VERSION "created by canmatrix"

NS_ :

BS_:

BU_:

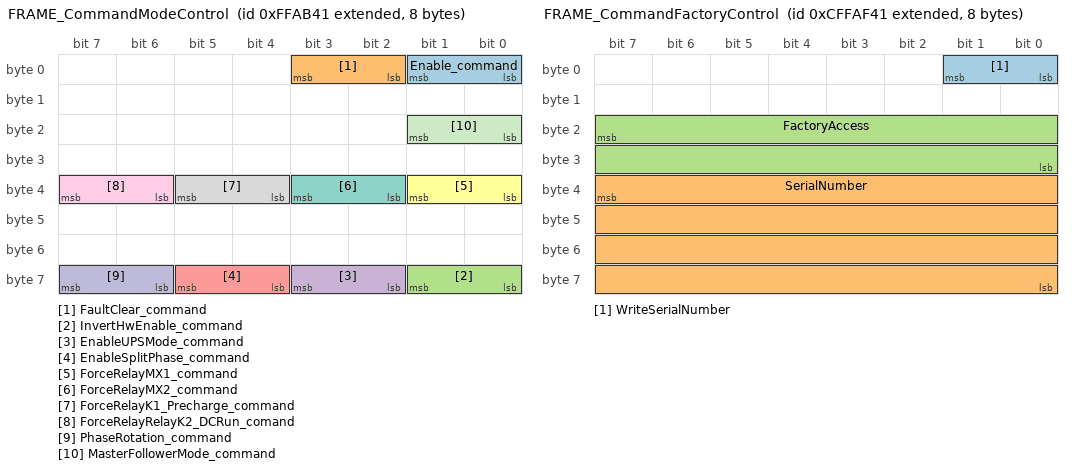
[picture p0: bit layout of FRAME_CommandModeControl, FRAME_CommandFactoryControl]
BO_ 2164239169 FRAME_CommandModeControl: 8 Vector__XXX
 SG_ Enable_command : 1|2@0+ (1,0) [0.0|3.0] "" Vector__XXX
 SG_ FaultClear_command : 3|2@0+ (1,0) [0.0|3.0] "" Vector__XXX
 SG_ InvertHwEnable_command : 57|2@0+ (1,0) [0.0|3.0] "" Vector__XXX
 SG_ EnableUPSMode_command : 59|2@0+ (1,0) [0.0|3.0] "" Vector__XXX
 SG_ EnableSplitPhase_command : 61|2@0+ (1,0) [0.0|3.0] "" Vector__XXX
 SG_ ForceRelayMX1_command : 33|2@0+ (1,0) [0.0|3.0] "" Vector__XXX
 SG_ ForceRelayMX2_command : 35|2@0+ (1,0) [0.0|3.0] "" Vector__XXX
 SG_ ForceRelayK1_Precharge_command : 37|2@0+ (1,0) [0.0|3.0] "" Vector__XXX
 SG_ ForceRelayRelayK2_DCRun_comand : 39|2@0+ (1,0) [0.0|3.0] "" Vector__XXX
 SG_ PhaseRotation_command : 63|2@0+ (1,0) [0.0|3.0] "" Vector__XXX
 SG_ MasterFollowerMode_command : 17|2@0+ (1,0) [0.0|3.0] "" Vector__XXX

BO_ 2365566017 FRAME_CommandPower: 8 Vector__XXX
 SG_ RealPower_command : 7|32@0+ (1,0) [0.0|4294967295.0] "" Vector__XXX
 SG_ ReactivePower_command : 39|32@0+ (1,0) [0.0|4294967295.0] "" Vector__XXX

BO_ 2365566529 FRAME_CommandVF: 8 Vector__XXX
 SG_ Voltage_command : 7|16@0+ (0.1,0) [0.0|6553.5] "" Vector__XXX
 SG_ Frequency_command : 23|16@0+ (0.1,0) [0.0|6553.5] "" Vector__XXX

BO_ 2365573878 FRAME_MasterMeasuredPower: 8 Vector__XXX
 SG_ RealPower_measured : 7|32@0+ (1,0) [0.0|4294967295.0] "" Vector__XXX
 SG_ ReactivePower_measured : 39|32@0+ (1,0) [0.0|4294967295.0] "" Vector__XXX

BO_ 2365566785 FRAME_CommandFactoryControl: 8 Vector__XXX
 SG_ WriteSerialNumber : 1|2@0+ (1,0) [0.0|3.0] "" Vector__XXX
 SG_ SerialNumber : 39|32@0+ (1,0) [0.0|4294967295.0] "" Vector__XXX
 SG_ FactoryAccess : 23|16@0+ (1,0) [0.0|65535.0] "" Vector__XXX

BO_ 2365565505 FRAME_CommandSetNVParam: 8 Vector__XXX
 SG_ CommandSetNVParam_MUX : 7|16@0+ (1,0) [0.0|65535.0] "" Vector__XXX
 SG_ Dummy : 23|16@0+ (1,0) [0.0|65535.0] "" Vector__XXX
 SG_ VUnder50pct : 23|16@0+ (1,0) [0.0|65535.0] "" Vector__XXX
 SG_ V50to88pct : 39|16@0+ (1,0) [0.0|65535.0] "" Vector__XXX
 SG_ V110to120pct : 55|16@0+ (1,0) [0.0|65535.0] "" Vector__XXX
 SG_ VOver120 : 23|16@0+ (1,0) [0.0|65535.0] "" Vector__XXX
 SG_ FreqHi : 23|16@0+ (0.1,0) [0.0|6553.5] "" Vector__XXX
 SG_ FreqLo : 39|16@0+ (0.1,0) [0.0|6553.5] "" Vector__XXX
 SG_ FreqVeryLo : 55|16@0+ (0.1,0) [0.0|6553.5] "" Vector__XXX
 SG_ FreqVeryLo : 23|16@0+ (0.1,0) [0.0|6553.5] "" Vector__XXX
 SG_ FreqLo : 39|16@0+ (0.1,0) [0.0|6553.5] "" Vector__XXX
 SG_ FreqHi : 55|16@0+ (0.1,0) [0.0|6553.5] "" Vector__XXX
 SG_ NodeID : 23|8@0+ (1,0) [0.0|255.0] "" Vector__XXX
 SG_ SA_Mask : 31|8@0+ (1,0) [0.0|255.0] "" Vector__XXX
 SG_ Baudrate : 39|4@0+ (1,0) [0.0|15.0] "" Vector__XXX
 SG_ ThermalOverload : 17|2@0+ (1,0) [0.0|3.0] "" Vector__XXX
 SG_ MX1Open : 23|16@0+ (1,0) [0.0|65535.0] "" Vector__XXX
 SG_ MX1Close : 39|16@0+ (1,0) [0.0|65535.0] "" Vector__XXX
 SG_ MX2Open : 55|16@0+ (1,0) [0.0|65535.0] "" Vector__XXX
 SG_ MX2Close : 23|16@0+ (1,0) [0.0|65535.0] "" Vector__XXX
 SG_ K1Open : 39|16@0+ (1,0) [0.0|65535.0] "" Vector__XXX
 SG_ K1Close : 55|16@0+ (1,0) [0.0|65535.0] "" Vector__XXX
 SG_ K2Open : 23|16@0+ (1,0) [0.0|65535.0] "" Vector__XXX
 SG_ K2Close : 39|16@0+ (1,0) [0.0|65535.0] "" Vector__XXX

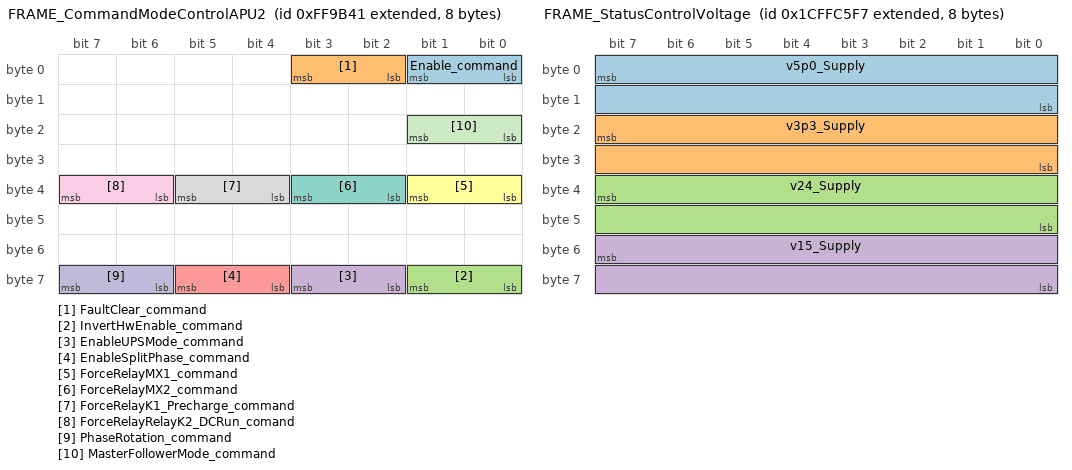
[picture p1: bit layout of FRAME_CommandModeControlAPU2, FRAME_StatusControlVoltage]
BO_ 2164235073 FRAME_CommandModeControlAPU2: 8 Vector__XXX
 SG_ Enable_command : 1|2@0+ (1,0) [0.0|3.0] "" Vector__XXX
 SG_ FaultClear_command : 3|2@0+ (1,0) [0.0|3.0] "" Vector__XXX
 SG_ InvertHwEnable_command : 57|2@0+ (1,0) [0.0|3.0] "" Vector__XXX
 SG_ EnableUPSMode_command : 59|2@0+ (1,0) [0.0|3.0] "" Vector__XXX
 SG_ EnableSplitPhase_command : 61|2@0+ (1,0) [0.0|3.0] "" Vector__XXX
 SG_ ForceRelayMX1_command : 33|2@0+ (1,0) [0.0|3.0] "" Vector__XXX
 SG_ ForceRelayMX2_command : 35|2@0+ (1,0) [0.0|3.0] "" Vector__XXX
 SG_ ForceRelayK1_Precharge_command : 37|2@0+ (1,0) [0.0|3.0] "" Vector__XXX
 SG_ ForceRelayRelayK2_DCRun_comand : 39|2@0+ (1,0) [0.0|3.0] "" Vector__XXX
 SG_ PhaseRotation_command : 63|2@0+ (1,0) [0.0|3.0] "" Vector__XXX
 SG_ MasterFollowerMode_command : 17|2@0+ (1,0) [0.0|3.0] "" Vector__XXX

BO_ 2365561921 FRAME_CommandPowerAPU2: 8 Vector__XXX
 SG_ RealPower_command : 7|32@0+ (1,0) [0.0|4294967295.0] "" Vector__XXX
 SG_ ReactivePower_command : 39|32@0+ (1,0) [0.0|4294967295.0] "" Vector__XXX

BO_ 2365562433 FRAME_CommandVFAPU2: 8 Vector__XXX
 SG_ Voltage_command : 7|16@0+ (0.1,0) [0.0|6553.5] "" Vector__XXX
 SG_ Frequency_command : 23|16@0+ (0.1,0) [0.0|6553.5] "" Vector__XXX

BO_ 2365573879 FRAME_MasterMeasuredPowerAPU2: 8 Vector__XXX
 SG_ RealPower_measured : 7|32@0+ (1,0) [0.0|4294967295.0] "" Vector__XXX
 SG_ ReactivePower_measured : 39|32@0+ (1,0) [0.0|4294967295.0] "" Vector__XXX

BO_ 2365573879 FRAME_StatusMeasuredPower: 8 Vector__XXX
 SG_ RealPower_measured : 7|32@0+ (1,0) [0.0|4294967295.0] "" Vector__XXX
 SG_ ReactivePower_measured : 39|32@0+ (1,0) [0.0|4294967295.0] "" Vector__XXX

BO_ 2566898935 FRAME_StatusCommandedPower: 8 Vector__XXX
 SG_ RealPower_echo : 7|32@0+ (1,0) [0.0|4294967295.0] "" Vector__XXX
 SG_ ReactivePower_echo : 39|32@0+ (1,0) [0.0|4294967295.0] "" Vector__XXX

BO_ 2365572087 FRAME_StatusBits: 8 Vector__XXX
 SG_ State_status : 3|4@0+ (1,0) [0.0|15.0] "" Vector__XXX
 SG_ MX2Permissive_status : 19|2@0+ (1,0) [0.0|3.0] "" Vector__XXX
 SG_ PowerAvailAC_status : 11|2@0+ (1,0) [0.0|3.0] "" Vector__XXX
 SG_ PowerAvailDC_status : 13|2@0+ (1,0) [0.0|3.0] "" Vector__XXX
 SG_ PowerCircuitEnabled_status : 15|2@0+ (1,0) [0.0|3.0] "" Vector__XXX
 SG_ HardwareEnable_status : 9|2@0+ (1,0) [0.0|3.0] "" Vector__XXX
 SG_ Enable_echo : 5|2@0+ (1,0) [0.0|3.0] "" Vector__XXX
 SG_ FaultClr_echo : 7|2@0+ (1,0) [0.0|3.0] "" Vector__XXX
 SG_ MessageValidModeControl_status : 25|2@0+ (1,0) [0.0|3.0] "" Vector__XXX
 SG_ MX1Permissive_status : 17|2@0+ (1,0) [0.0|3.0] "" Vector__XXX
 SG_ K2DCRunPermissive_status : 23|2@0+ (1,0) [0.0|3.0] "" Vector__XXX
 SG_ K1PrechargePermissive_status : 21|2@0+ (1,0) [0.0|3.0] "" Vector__XXX
 SG_ MessageValidPowerCMD_status : 27|2@0+ (1,0) [0.0|3.0] "" Vector__XXX
 SG_ MessageValidVF_status : 29|2@0+ (1,0) [0.0|3.0] "" Vector__XXX
 SG_ CANbus_status : 31|2@0+ (1,0) [0.0|3.0] "" Vector__XXX
 SG_ EnableUPSMode_echo : 33|2@0+ (1,0) [0.0|3.0] "" Vector__XXX
 SG_ EnableSplitPhase_echo : 35|2@0+ (1,0) [0.0|3.0] "" Vector__XXX
 SG_ PhaseRotation_status : 37|2@0+ (1,0) [0.0|3.0] "" Vector__XXX
 SG_ LineVoltageDetected_status : 39|2@0+ (1,0) [0.0|3.0] "" Vector__XXX
 SG_ PhaseRotation_echo : 41|2@0+ (1,0) [0.0|3.0] "" Vector__XXX

BO_ 2634008055 FRAME_StatusControlVoltage: 8 Vector__XXX
 SG_ v5p0_Supply : 7|16@0+ (0.01,0) [0.0|655.35] "" Vector__XXX
 SG_ v3p3_Supply : 23|16@0+ (0.01,0) [0.0|655.35] "" Vector__XXX
 SG_ v24_Supply : 39|16@0+ (0.01,0) [0.0|655.35] "" Vector__XXX
 SG_ v15_Supply : 55|16@0+ (0.01,0) [0.0|655.35] "" Vector__XXX

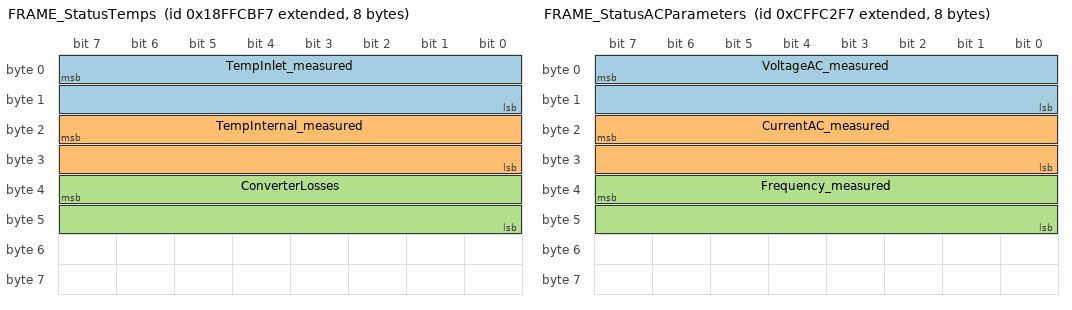
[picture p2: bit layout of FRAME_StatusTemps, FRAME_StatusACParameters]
BO_ 2566900727 FRAME_StatusTemps: 8 Vector__XXX
 SG_ TempInlet_measured : 7|16@0+ (0.1,0) [0.0|6553.5] "" Vector__XXX
 SG_ TempInternal_measured : 23|16@0+ (0.1,0) [0.0|6553.5] "" Vector__XXX
 SG_ ConverterLosses : 39|16@0+ (1,0) [0.0|65535.0] "" Vector__XXX

BO_ 2365573367 FRAME_StatusFaults: 8 Vector__XXX
 SG_ BridgeAVoltageOk_status : 59|1@0+ (1,0) [0.0|1.0] "" Vector__XXX
 SG_ OvercurrentAC_status : 3|2@0+ (1,0) [0.0|3.0] "" Vector__XXX
 SG_ BridgeBVoltageOk_status : 43|1@0+ (1,0) [0.0|1.0] "" Vector__XXX
 SG_ OvervoltageDC_status : 9|2@0+ (1,0) [0.0|3.0] "" Vector__XXX
 SG_ OvertempPowerDevice_status : 15|2@0+ (1,0) [0.0|3.0] "" Vector__XXX
 SG_ OvertempInternal_status : 13|2@0+ (1,0) [0.0|3.0] "" Vector__XXX
 SG_ LossValidControlMessage_status : 23|4@0+ (1,0) [0.0|15.0] "" Vector__XXX
 SG_ UndervoltageDC_status : 11|2@0+ (1,0) [0.0|3.0] "" Vector__XXX
 SG_ ControlHardwareFail_status : 19|4@0+ (1,0) [0.0|15.0] "" Vector__XXX
 SG_ OvercurrentDC_status : 7|2@0+ (1,0) [0.0|3.0] "" Vector__XXX
 SG_ GeneralFault_status : 1|2@0+ (1,0) [0.0|3.0] "" Vector__XXX
 SG_ LossOfAC_status : 5|2@0+ (1,0) [0.0|3.0] "" Vector__XXX
 SG_ EStopShutdown_status : 25|2@0+ (1,0) [0.0|3.0] "" Vector__XXX
 SG_ BridgeAFault_status : 58|3@0+ (1,0) [0.0|7.0] "" Vector__XXX
 SG_ BridgeBFault_status : 42|3@0+ (1,0) [0.0|7.0] "" Vector__XXX
 SG_ IllegalTransition_status : 27|2@0+ (1,0) [0.0|3.0] "" Vector__XXX
 SG_ InvalidEEHeader_status : 29|2@0+ (1,0) [0.0|3.0] "" Vector__XXX
 SG_ InvalidEESection_status : 31|2@0+ (1,0) [0.0|3.0] "" Vector__XXX
 SG_ ThermalOverload : 33|2@0+ (1,0) [0.0|3.0] "" Vector__XXX

BO_ 2365571831 FRAME_StatusACParameters: 8 Vector__XXX
 SG_ VoltageAC_measured : 7|16@0+ (0.1,0) [0.0|6553.5] "" Vector__XXX
 SG_ CurrentAC_measured : 23|16@0+ (1,0) [0.0|65535.0] "" Vector__XXX
 SG_ Frequency_measured : 39|16@0+ (0.1,0) [0.0|6553.5] "" Vector__XXX

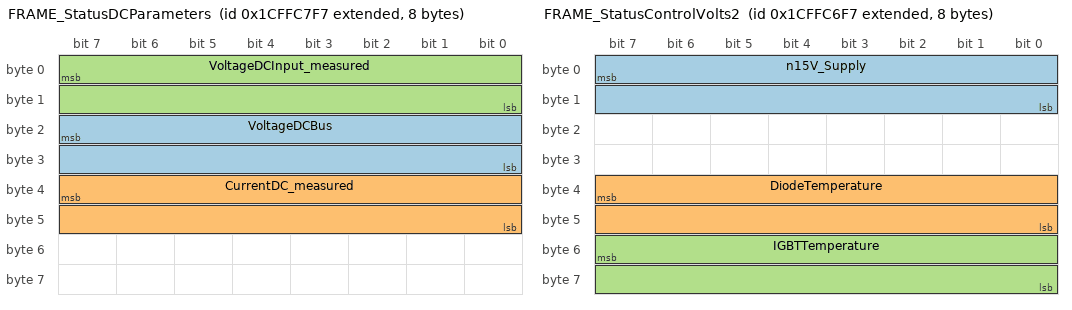
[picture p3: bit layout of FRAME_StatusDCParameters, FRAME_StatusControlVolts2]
BO_ 2634008567 FRAME_StatusDCParameters: 8 Vector__XXX
 SG_ VoltageDCBus : 23|16@0+ (1,0) [0.0|65535.0] "" Vector__XXX
 SG_ CurrentDC_measured : 39|16@0+ (1,0) [0.0|65535.0] "" Vector__XXX
 SG_ VoltageDCInput_measured : 7|16@0+ (1,0) [0.0|65535.0] "" Vector__XXX

BO_ 2634008311 FRAME_StatusControlVolts2: 8 Vector__XXX
 SG_ n15V_Supply : 7|16@0+ (0.01,0) [0.0|655.35] "" Vector__XXX
 SG_ DiodeTemperature : 39|16@0+ (1,0) [0.0|65535.0] "" Vector__XXX
 SG_ IGBTTemperature : 55|16@0+ (1,0) [0.0|65535.0] "" Vector__XXX

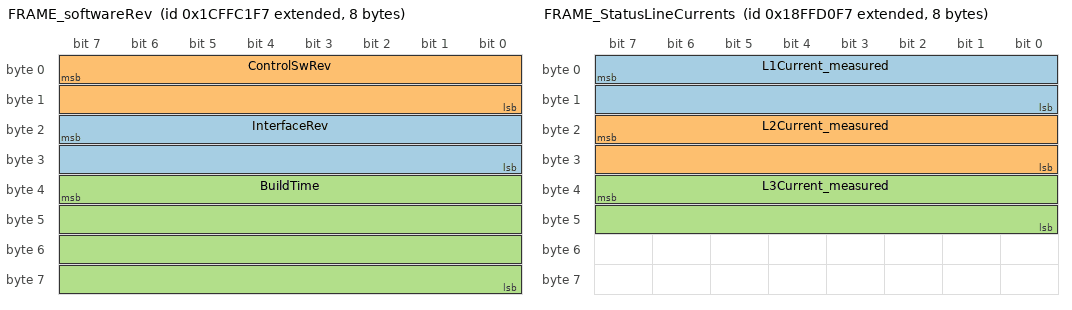
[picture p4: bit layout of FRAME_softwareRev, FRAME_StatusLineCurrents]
BO_ 2634007031 FRAME_softwareRev: 8 Vector__XXX
 SG_ InterfaceRev : 23|16@0+ (0.01,0) [0.0|655.35] "" Vector__XXX
 SG_ ControlSwRev : 7|16@0+ (0.01,0) [0.0|655.35] "" Vector__XXX
 SG_ BuildTime : 39|32@0+ (1,0) [0.0|4294967295.0] "" Vector__XXX

BO_ 2566900215 FRAME_StatusCommandVF: 8 Vector__XXX
 SG_ Voltage_echo : 7|16@0+ (0.1,0) [0.0|6553.5] "" Vector__XXX
 SG_ Frequency_echo : 23|16@0+ (0.1,0) [0.0|6553.5] "" Vector__XXX

BO_ 2634009847 FRAME_serialNumber: 8 Vector__XXX
 SG_ SerialNumber : 7|32@0+ (1,0) [0.0|4294967295.0] "" Vector__XXX

BO_ 2634010103 FRAME_softwareRevHash: 8 Vector__XXX
 SG_ Hash : 7|28@0+ (1,0) [0.0|268435455.0] "" Vector__XXX

BO_ 2634000887 FRAME_StatusNVParam: 8 Vector__XXX
 SG_ StatusNVParam_MUX : 7|16@0+ (1,0) [0.0|65535.0] "" Vector__XXX
 SG_ Dummy : 23|16@0+ (1,0) [0.0|65535.0] "" Vector__XXX
 SG_ VUnder50pct : 23|16@0+ (1,0) [0.0|65535.0] "" Vector__XXX
 SG_ V50to88pct : 39|16@0+ (1,0) [0.0|65535.0] "" Vector__XXX
 SG_ V110to120pct : 55|16@0+ (1,0) [0.0|65535.0] "" Vector__XXX
 SG_ VOver120 : 23|16@0+ (1,0) [0.0|65535.0] "" Vector__XXX
 SG_ FreqHi : 23|16@0+ (0.1,0) [0.0|6553.5] "" Vector__XXX
 SG_ FreqLo : 39|16@0+ (0.1,0) [0.0|6553.5] "" Vector__XXX
 SG_ FreqVeryLo : 55|16@0+ (0.1,0) [0.0|6553.5] "" Vector__XXX
 SG_ FreqVeryLo : 23|16@0+ (0.1,0) [0.0|6553.5] "" Vector__XXX
 SG_ FreqLo : 39|16@0+ (0.1,0) [0.0|6553.5] "" Vector__XXX
 SG_ FreqHi : 55|16@0+ (0.1,0) [0.0|6553.5] "" Vector__XXX
 SG_ StatusNodeID : 23|8@0+ (1,0) [0.0|255.0] "" Vector__XXX
 SG_ StatusSA_Mask : 31|8@0+ (1,0) [0.0|255.0] "" Vector__XXX
 SG_ StatusBaudrate : 39|4@0+ (1,0) [0.0|15.0] "" Vector__XXX
 SG_ StatusThermalOverload : 17|2@0+ (1,0) [0.0|3.0] "" Vector__XXX
 SG_ StatusMX1Open : 23|16@0+ (1,0) [0.0|65535.0] "" Vector__XXX
 SG_ StatusMX1Close : 39|16@0+ (1,0) [0.0|65535.0] "" Vector__XXX
 SG_ StatusMX2Open : 55|16@0+ (1,0) [0.0|65535.0] "" Vector__XXX
 SG_ StatusMX2Close : 23|16@0+ (1,0) [0.0|65535.0] "" Vector__XXX
 SG_ StatusK1Open : 39|16@0+ (1,0) [0.0|65535.0] "" Vector__XXX
 SG_ StatusK1Close : 55|16@0+ (1,0) [0.0|65535.0] "" Vector__XXX
 SG_ StatusK2Open : 23|16@0+ (1,0) [0.0|65535.0] "" Vector__XXX
 SG_ StatusK2Close : 39|16@0+ (1,0) [0.0|65535.0] "" Vector__XXX

BO_ 2566902007 FRAME_StatusLineCurrents: 8 Vector__XXX
 SG_ L1Current_measured : 7|16@0+ (1,0) [0.0|65535.0] "" Vector__XXX
 SG_ L2Current_measured : 23|16@0+ (1,0) [0.0|65535.0] "" Vector__XXX
 SG_ L3Current_measured : 39|16@0+ (1,0) [0.0|65535.0] "" Vector__XXX

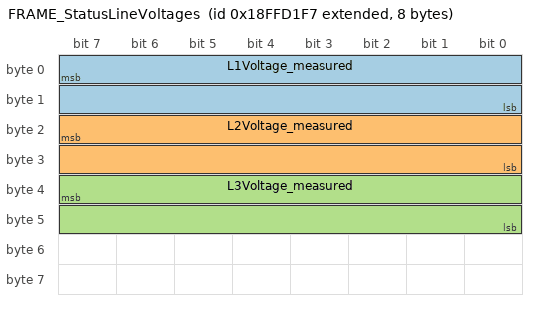
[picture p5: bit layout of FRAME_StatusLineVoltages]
BO_ 2566902263 FRAME_StatusLineVoltages: 8 Vector__XXX
 SG_ L1Voltage_measured : 7|16@0+ (0.1,0) [0.0|6553.5] "" Vector__XXX
 SG_ L2Voltage_measured : 23|16@0+ (0.1,0) [0.0|6553.5] "" Vector__XXX
 SG_ L3Voltage_measured : 39|16@0+ (0.1,0) [0.0|6553.5] "" Vector__XXX

BA_DEF_ BO_ "GenMsgSendType" ENUM  "cyclicX","spontanX","cyclicIfActiveX","spontanWithDelay","cyclicAndSpontanX","cyclicAndSpontanWithDelay","spontanWithRepitition","cyclicIfActiveAndSpontanWD","cyclicIfActiveFast","cyclicWithRepeatOnDemand","none";
BA_DEF_ BO_ "GenMsgStartValue" STRING;

BA_ "GenMsgSendType" BO_ 2164239169 1;
BA_ "GenMsgStartValue" BO_ 2164239169 "0000000000000000";
BA_ "GenMsgSendType" BO_ 2365566017 1;
BA_ "GenMsgStartValue" BO_ 2365566017 "0000000000000000";
BA_ "GenMsgSendType" BO_ 2365566529 1;
BA_ "GenMsgStartValue" BO_ 2365566529 "0000000000000000";
BA_ "GenMsgSendType" BO_ 2365573878 1;
BA_ "GenMsgStartValue" BO_ 2365573878 "0000000000000000";
BA_ "GenMsgSendType" BO_ 2365566785 1;
BA_ "GenMsgStartValue" BO_ 2365566785 "0000000000000000";
BA_ "GenMsgSendType" BO_ 2365565505 1;
BA_ "GenMsgStartValue" BO_ 2365565505 "0000000000000000";
BA_ "GenMsgSendType" BO_ 2164235073 1;
BA_ "GenMsgStartValue" BO_ 2164235073 "0000000000000000";
BA_ "GenMsgSendType" BO_ 2365561921 1;
BA_ "GenMsgStartValue" BO_ 2365561921 "0000000000000000";
BA_ "GenMsgSendType" BO_ 2365562433 1;
BA_ "GenMsgStartValue" BO_ 2365562433 "0000000000000000";
BA_ "GenMsgSendType" BO_ 2365573879 1;
BA_ "GenMsgStartValue" BO_ 2365573879 "0000000000000000";
BA_ "GenMsgSendType" BO_ 2365573879 1;
BA_ "GenMsgStartValue" BO_ 2365573879 "0000000000000000";
BA_ "GenMsgSendType" BO_ 2566898935 1;
BA_ "GenMsgStartValue" BO_ 2566898935 "0000000000000000";
BA_ "GenMsgSendType" BO_ 2365572087 1;
BA_ "GenMsgStartValue" BO_ 2365572087 "0000000000000000";
BA_ "GenMsgSendType" BO_ 2634008055 1;
BA_ "GenMsgStartValue" BO_ 2634008055 "0000000000000000";
BA_ "GenMsgSendType" BO_ 2566900727 1;
BA_ "GenMsgStartValue" BO_ 2566900727 "0000000000000000";
BA_ "GenMsgSendType" BO_ 2365573367 1;
BA_ "GenMsgStartValue" BO_ 2365573367 "0000000000000000";
BA_ "GenMsgSendType" BO_ 2365571831 1;
BA_ "GenMsgStartValue" BO_ 2365571831 "0000000000000000";
BA_ "GenMsgSendType" BO_ 2634008567 1;
BA_ "GenMsgStartValue" BO_ 2634008567 "0000000000000000";
BA_ "GenMsgSendType" BO_ 2634008311 1;
BA_ "GenMsgStartValue" BO_ 2634008311 "0000000000000000";
BA_ "GenMsgSendType" BO_ 2634007031 1;
BA_ "GenMsgStartValue" BO_ 2634007031 "0000000000000000";
BA_ "GenMsgSendType" BO_ 2566900215 1;
BA_ "GenMsgStartValue" BO_ 2566900215 "0000000000000000";
BA_ "GenMsgSendType" BO_ 2634009847 1;
BA_ "GenMsgStartValue" BO_ 2634009847 "0000000000000000";
BA_ "GenMsgSendType" BO_ 2634010103 1;
BA_ "GenMsgStartValue" BO_ 2634010103 "0000000000000000";
BA_ "GenMsgSendType" BO_ 2634000887 1;
BA_ "GenMsgStartValue" BO_ 2634000887 "0000000000000000";
BA_ "GenMsgSendType" BO_ 2566902007 1;
BA_ "GenMsgStartValue" BO_ 2566902007 "0000000000000000";
BA_ "GenMsgSendType" BO_ 2566902263 1;
BA_ "GenMsgStartValue" BO_ 2566902263 "0000000000000000";

VAL_ 2164239169 Enable_command 0 "Disable" 1 "Enable" 2 "Error" 3 "N/A";
VAL_ 2164239169 FaultClear_command 0 "Normal" 1 "Clear Faults" 2 "Error" 3 "N/A";
VAL_ 2164239169 InvertHwEnable_command 0 "No invert" 1 "Invert" 2 "Error" 3 "N/A";
VAL_ 2164239169 EnableUPSMode_command 0 "Disable" 1 "Enable" 2 "Error" 3 "N/A";
VAL_ 2164239169 EnableSplitPhase_command 0 "Normal - Three Phase Mode" 1 "Enable Split Phase Mode" 2 "Error" 3 "N/A";
VAL_ 2164239169 ForceRelayMX1_command 0 "Normal" 1 "Force On" 2 "Error" 3 "N/A";
VAL_ 2164239169 ForceRelayMX2_command 0 "Normal" 1 "Force On" 2 "Error" 3 "N/A";
VAL_ 2164239169 ForceRelayK1_Precharge_command 0 "Normal" 1 "Force On" 2 "Error" 3 "N/A";
VAL_ 2164239169 ForceRelayRelayK2_DCRun_comand 0 "Normal" 1 "Force On" 2 "Error" 3 "N/A";
VAL_ 2164239169 PhaseRotation_command 0 "Negative" 1 "Positive" 2 "Error" 3 "N/A";
VAL_ 2164239169 MasterFollowerMode_command 0 "Master" 1 "Follower" 2 "Error" 3 "N/A";
VAL_ 2365566785 WriteSerialNumber 0 "Disable" 1 "Enable" 2 "Error" 3 "N/A";
VAL_ 2365565505 CommandSetNVParam_MUX 0 "Param0" 1 "LVM_ClearingTimes1" 2 "LVM_ClearingTimes2" 3 "LFM_Limits" 4 "LFM_ClearingTimes" 5 "J1939_Interface" 6 "Fault_Config" 7 "ContactorDelays1" 8 "ContactorDelays2" 9 "ContactorDelays3";
VAL_ 2365565505 Baudrate 0 "125K" 1 "250K" 2 "500K" 3 "1M";
VAL_ 2365565505 ThermalOverload 0 "Warning" 1 "Fault" 2 "Error" 3 "N/A";
VAL_ 2164235073 Enable_command 0 "Disable" 1 "Enable" 2 "Error" 3 "N/A";
VAL_ 2164235073 FaultClear_command 0 "Normal" 1 "Clear Faults" 2 "Error" 3 "N/A";
VAL_ 2164235073 InvertHwEnable_command 0 "No invert" 1 "Invert" 2 "Error" 3 "N/A";
VAL_ 2164235073 EnableUPSMode_command 0 "Disable" 1 "Enable" 2 "Error" 3 "N/A";
VAL_ 2164235073 EnableSplitPhase_command 0 "Normal - Three Phase Mode" 1 "Enable Split Phase Mode" 2 "Error" 3 "N/A";
VAL_ 2164235073 ForceRelayMX1_command 0 "Normal" 1 "Force On" 2 "Error" 3 "N/A";
VAL_ 2164235073 ForceRelayMX2_command 0 "Normal" 1 "Force On" 2 "Error" 3 "N/A";
VAL_ 2164235073 ForceRelayK1_Precharge_command 0 "Normal" 1 "Force On" 2 "Error" 3 "N/A";
VAL_ 2164235073 ForceRelayRelayK2_DCRun_comand 0 "Normal" 1 "Force On" 2 "Error" 3 "N/A";
VAL_ 2164235073 PhaseRotation_command 0 "Negative" 1 "Positive" 2 "Error" 3 "N/A";
VAL_ 2164235073 MasterFollowerMode_command 0 "Master" 1 "Follower" 2 "Error" 3 "N/A";
VAL_ 2365572087 State_status 0 "Power On Reset" 1 "Ready" 2 "Following" 3 "Fault" 4 "Forming" 5 "N/A" 6 "N/A" 7 "N/A" 8 "N/A" 9 "N/A" 10 "N/A" 11 "N/A" 12 "N/A" 13 "N/A" 14 "N/A" 15 "N/A";
VAL_ 2365572087 MX2Permissive_status 0 "Open" 1 "Closed" 2 "Error" 3 "N/A";
VAL_ 2365572087 PowerAvailAC_status 0 "None" 1 "Available" 2 "Error" 3 "N/A";
VAL_ 2365572087 PowerAvailDC_status 0 "None" 1 "Available" 2 "Error" 3 "N/A";
VAL_ 2365572087 PowerCircuitEnabled_status 0 "Disabled" 1 "Enabled" 2 "Error" 3 "N/A";
VAL_ 2365572087 HardwareEnable_status 0 "Not Active" 1 "Active" 2 "Error" 3 "N/A";
VAL_ 2365572087 Enable_echo 0 "Disable" 1 "Enable" 2 "Error" 3 "N/A";
VAL_ 2365572087 FaultClr_echo 0 "Normal" 1 "Clear Faults" 2 "Error" 3 "N/A";
VAL_ 2365572087 MessageValidModeControl_status 0 "Invalid" 1 "Valid" 2 "Error" 3 "N/A";
VAL_ 2365572087 MX1Permissive_status 0 "Open" 1 "Closed" 2 "Error" 3 "N/A";
VAL_ 2365572087 K2DCRunPermissive_status 0 "Open" 1 "Closed" 2 "Error" 3 "N/A";
VAL_ 2365572087 K1PrechargePermissive_status 0 "Open" 1 "Closed" 2 "Error" 3 "N/A";
VAL_ 2365572087 MessageValidPowerCMD_status 0 "Invalid" 1 "Valid" 2 "Error" 3 "N/A";
VAL_ 2365572087 MessageValidVF_status 0 "Invalid" 1 "Valid" 2 "Error" 3 "N/A";
VAL_ 2365572087 CANbus_status 0 "Normal" 1 "Warning" 3 "ErrorPassive" 4 "N/A";
VAL_ 2365572087 EnableUPSMode_echo 0 "Disable" 1 "Enable" 2 "Error" 3 "N/A";
VAL_ 2365572087 EnableSplitPhase_echo 0 "Normal - Three Phase Mode" 1 "Enable Split Phase Mode" 2 "Error" 3 "N/A";
VAL_ 2365572087 PhaseRotation_status 0 "Negative" 1 "Positive" 2 "Error" 3 "N/A";
VAL_ 2365572087 LineVoltageDetected_status 0 "No_Voltage" 1 "Voltage_Detected" 2 "Error" 3 "N/A";
VAL_ 2365572087 PhaseRotation_echo 0 "Negative" 1 "Positive" 2 "Error" 3 "N/A";
VAL_ 2365573367 BridgeAVoltageOk_status 0 "Normal" 1 "Fault Active" 2 "Error" 3 "N/A";
VAL_ 2365573367 OvercurrentAC_status 0 "Normal" 1 "Fault Active" 2 "Error" 3 "N/A";
VAL_ 2365573367 BridgeBVoltageOk_status 0 "Normal" 1 "Fault Active" 2 "Error" 3 "N/A";
VAL_ 2365573367 OvervoltageDC_status 0 "Normal" 1 "Fault Active" 2 "Error" 3 "N/A";
VAL_ 2365573367 OvertempPowerDevice_status 0 "Normal" 1 "Fault Active" 2 "Error" 3 "N/A";
VAL_ 2365573367 OvertempInternal_status 0 "Normal" 1 "Fault Active" 2 "Error" 3 "N/A";
VAL_ 2365573367 LossValidControlMessage_status 0 "Normal" 1 "Fault Active" 2 "Error" 3 "N/A";
VAL_ 2365573367 UndervoltageDC_status 0 "Normal" 1 "Fault Active" 2 "Error" 3 "N/A";
VAL_ 2365573367 ControlHardwareFail_status 0 "Normal" 1 "Fault Active" 2 "Error" 3 "N/A";
VAL_ 2365573367 OvercurrentDC_status 0 "Normal" 1 "Fault Active" 2 "Error" 3 "N/A";
VAL_ 2365573367 GeneralFault_status 0 "Normal" 1 "Fault Active" 2 "Error" 3 "N/A";
VAL_ 2365573367 LossOfAC_status 0 "Normal" 1 "Fault Active" 2 "Error" 3 "N/A";
VAL_ 2365573367 EStopShutdown_status 0 "Normal" 1 "Fault Active" 2 "Error" 3 "N/A";
VAL_ 2365573367 BridgeAFault_status 0 "Normal" 1 "FLT_A" 2 "N/A" 3 "FLT_C" 4 "OverVoltage" 5 "FLT_B" 6 "Overcurrent" 7 "5V";
VAL_ 2365573367 BridgeBFault_status 0 "Normal" 1 "FLT_A" 2 "N/A" 3 "FLT_C" 4 "OverVoltage" 5 "FLT_B" 6 "Overcurrent" 7 "5V";
VAL_ 2365573367 IllegalTransition_status 0 "Normal" 1 "Fault Active" 2 "Error" 3 "N/A";
VAL_ 2365573367 InvalidEEHeader_status 0 "Normal" 1 "Fault Active" 2 "Error" 3 "N/A";
VAL_ 2365573367 InvalidEESection_status 0 "Normal" 1 "Fault Active" 2 "Error" 3 "N/A";
VAL_ 2365573367 ThermalOverload 0 "Warning" 1 "Fault" 2 "Error" 3 "N/A";
VAL_ 2634000887 StatusNVParam_MUX 0 "ActParam0" 1 "ActLVM_ClearingTimes1" 2 "ActLVM_ClearingTimes2" 3 "ActLFM_Limits" 4 "ActLFM_ClearingTimes" 5 "StatusJ1939_Interface" 6 "StatusFault_Config" 7 "StatusContactorDelays1" 8 "StatusContactorDelays2" 9 "StatusContactorDelays3";
VAL_ 2634000887 StatusBaudrate 0 "125K" 1 "250K" 2 "500K" 3 "1M";
VAL_ 2634000887 StatusThermalOverload 0 "Warning" 1 "Fault" 2 "Error" 3 "N/A";
